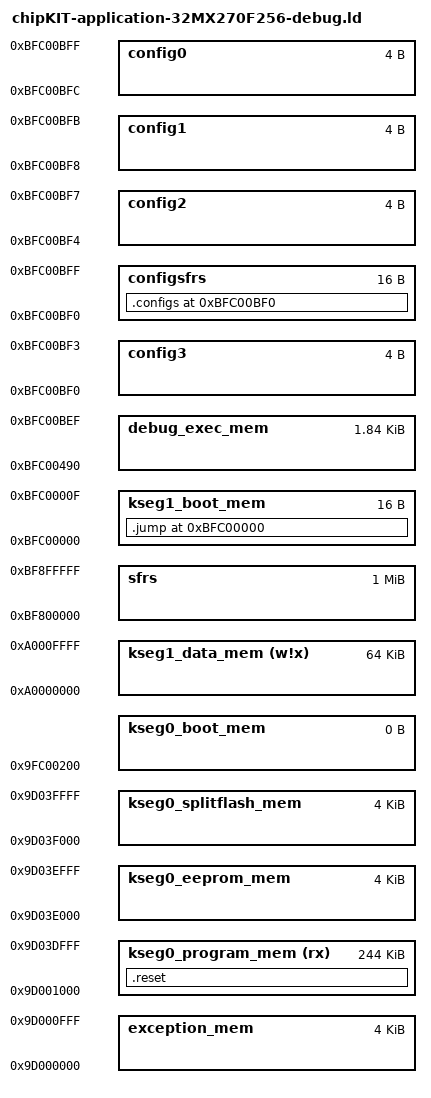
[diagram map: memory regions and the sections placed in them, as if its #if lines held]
/* Default linker script, for normal executables */
OUTPUT_FORMAT("elf32-tradlittlemips")
OUTPUT_ARCH(pic32mx)
ENTRY(_reset)
/*
 * Provide for a minimum stack and heap size
 * - _min_stack_size - represents the minimum space that must be made
 *                     available for the stack.  Can be overridden from
 *                     the command line using the linker's --defsym option.
 * - _min_heap_size  - represents the minimum space that must be made
 *                     available for the heap.  Can be overridden from
 *                     the command line using the linker's --defsym option.
 */
EXTERN (_min_stack_size _min_heap_size)
PROVIDE(_min_stack_size = 0x800) ;
PROVIDE(_min_heap_size = 0x800) ;

/*************************************************************************
 * Processor-specific object file.  Contains SFR definitions.
 *************************************************************************/
INPUT("processor.o")
OPTIONAL("libmchp_peripheral_32MX250F128D.a") 

/*************************************************************************
 * Memory Regions
 *
 * Memory regions without attributes cannot be used for orphaned sections.
 * Only sections specifically assigned to these regions can be allocated
 * into these regions.
 *************************************************************************/
MEMORY
{
  exception_mem              : ORIGIN = 0x9D000000, LENGTH = 0x1000
  kseg0_program_mem    (rx)  : ORIGIN = 0x9D001000, LENGTH = 0x3D000
  kseg0_eeprom_mem           : ORIGIN = 0x9D03E000, LENGTH = 0x1000
  kseg0_splitflash_mem       : ORIGIN = 0x9D03F000, LENGTH = 0x1000
  kseg0_boot_mem             : ORIGIN = 0x9FC00200, LENGTH = 0
#if defined(__DEBUG_D)
  kseg1_boot_mem             : ORIGIN = 0xBFC00000, LENGTH = 0x10 
  debug_exec_mem             : ORIGIN = 0xBFC00490, LENGTH = 0x760
#else
  kseg1_boot_mem             : ORIGIN = 0xBFC00000, LENGTH = 0xBF0 
  debug_exec_mem             : ORIGIN = 0xBFC00490, LENGTH = 0
#endif
  config3                    : ORIGIN = 0xBFC00BF0, LENGTH = 0x4
  config2                    : ORIGIN = 0xBFC00BF4, LENGTH = 0x4
  config1                    : ORIGIN = 0xBFC00BF8, LENGTH = 0x4
  config0                    : ORIGIN = 0xBFC00BFC, LENGTH = 0x4
  kseg1_data_mem       (w!x) : ORIGIN = 0xA0000000, LENGTH = 0x10000
  sfrs                       : ORIGIN = 0xBF800000, LENGTH = 0x100000
  configsfrs                 : ORIGIN = 0xBFC00BF0, LENGTH = 0x10
}

/*************************************************************************
 * Memory Address Equates
 *************************************************************************/
_ebase_address  	    = ORIGIN(exception_mem);
_IMAGE_PTR_TABLE       	= _ebase_address + 0x0F8;
_IMAGE_HEADER_ADDR      = _ebase_address + 0x0FC;
_GEN_EXCPT_ADDR         = _ebase_address + 0x180;
_RESET_ADDR             = ORIGIN(kseg0_program_mem);
_EEPROM_ADDR            = ORIGIN(kseg0_eeprom_mem);
_BEV_EXCPT_ADDR         = 0xBFC00380;
_DBG_EXCPT_ADDR         = 0xBFC00480;
_DBG_CODE_ADDR          = ORIGIN(debug_exec_mem);

/*************************************************************************
 *  Bootloader program directives.
 *  
 * _IMAGE_TYPE
 *
 *  image type:
 */
     
_imageReserved                      = 0x00000000 ;
_imageMPIDE                         = 0x00000001 ;  /* This is a normal MPIDE sketch                                                                                                    */
_imageBootFlashBootloader           = 0x00000002 ;  /* This is a boot flash bootloader                                                                                                  */
_imageProgramFlashBootloader        = 0x00000004 ;  /* This is a program flash bootloader                                                                                               */
_imageSplitFlashBootloader          = 0x00000008 ;  /* This has bootloader code in both boot and program flash                                                                          */

 /*
 *  Instructions for the bootloader
 */
                                                                       
_imageFullFlashEraseLess4KEEProm    = 0x00010000 ;  /* The original bootloader method of erasing all of program flash except the last 4K reserved for eeprom                            */
_imageJustInTimeFlashErase          = 0x00020000 ;  /* Only flash pages written too needed by the sketch is erased                                                                      */
_imageLinkerSpecifiedFlashErase     = 0x00040000 ;  /* The linker defines the flash range to erase                                                                                      */
_imageFullFlashErase                = 0x00080000 ;  /* All of flash is erased                                                                                                           */
_imageExecutionJumpAddress          = 0x01000000 ;  /* the bootloader will jump to the execution jump address immediately after programming                                             */
_imageExecutionJumpToFirstInFlash   = 0x02000000 ;  /* the bootloader will jump to the first sketch loaded in flash ignoring the execution jump address immediately after programming   */
 
/*  
 * _IMAGE_FLASH_SIZE 
 *
 *      Typically _imageJustInTimeFlashErase is selected to just erase the pages
 *      of flash that code is written too; thus leaving all other flash pages untouched.
 *  
 *      If _imageLinkerSpecifiedFlashErase set, then the range
 *      starting from _ebase_address for _IMAGE_FLASH_SIZE bytes are erased.
 *
 *      If _imageFullFlashErase is specified, than the whole flash
 *      as known by the bootloader will be erased. This will erase eeprom as well
 *
 *      if _imageFullFlashEraseLess4KEEProm is set, all of flash less the last 4K is
 *      erased, this is the old default. This bit could be set to make a program flash bootloader
 *      erasing everything but the old flash. If NOTHING is set, this will be the default as this is the old behavior.
 *  
 *  _JUMP_ADDR
 *  
 *      This is the address that the bootloader will jump to start execution
 *      of the sketch. This is almost always _RESET_ADDR.
 *
 *      However, you can specify an alternate entry execution point for example
 *      if you have alternate starup code that, say, shared
 *      the runtime with other sketches or needed some kind of specific handling
 *
 *      Immediately after programming (avrdude upload) the bootloader will typically
 *      jump to the just loaded sketch, no matter where it was loaded in flash.
 *      _imageExecutionJumpToFirstInFlash will tell the bootloader to jump to the first
 *      sketch in flash even if the just loaded one is not at the beginning of flash.
 *      This is useful when programming sketches in slots of flash and then always
 *      jumping to the program-flash loader (vector sketch) as if the board was just reset.
 *      This bit does not effect jumping to a sketch already in flash after reset.
 *      As of today, after reset, the first program in flash will always be jumped to.
 *
 *************************************************************************/
 _IMAGE_TYPE            = _imageMPIDE | _imageJustInTimeFlashErase | _imageExecutionJumpAddress;
 _IMAGE_FLASH_SIZE      = LENGTH(exception_mem) + LENGTH(kseg0_program_mem);
_JUMP_ADDR              = _RESET_ADDR;

SECTIONS
{
#if defined(__DEBUG_D)
  /* Jump from reset vector */
  .jump ORIGIN(kseg1_boot_mem): {
    LONG(0x3C1F9D00)  /* lui ra 0x9d00 */
	LONG(0x37FF1000)  /* ori ra 0x1000 */
	LONG(0x03E00008)  /* jr ra */
	LONG(0x00000000)  /* nop */
  } > kseg1_boot_mem
#else
  /* Insert bootloader */
  .jump ORIGIN(kseg1_boot_mem): {
	LONG(0x401A6000)	/* 0x1FC0_0000 */
	LONG(0x7F5A04C0)	/* 0x1FC0_0004 */
	LONG(0x13400006)	/* 0x1FC0_0008 */
	LONG(0x401A6000)	/* 0x1FC0_000C */
	LONG(0x3C1BFFBF)	/* 0x1FC0_0010 */
	LONG(0x377BFFFF)	/* 0x1FC0_0014 */
	LONG(0x35BD024)		/* 0x1FC0_0018 */
	LONG(0x409A6000)	/* 0x1FC0_001C */
	LONG(0x42000018)	/* 0x1FC0_0020 */
	LONG(0x3C1DA000)	/* 0x1FC0_0024 */
	LONG(0x27BD3FF8)	/* 0x1FC0_0028 */
	LONG(0x3C1CA001)	/* 0x1FC0_002C */
	LONG(0x279C85F0)	/* 0x1FC0_0030 */
	LONG(0x40096002)	/* 0x1FC0_0034 */
	LONG(0x1205820)		/* 0x1FC0_0038 */
	LONG(0x7D2A1E80)	/* 0x1FC0_003C */
	LONG(0x7D494984)	/* 0x1FC0_0040 */
	LONG(0x40896002)	/* 0x1FC0_0044 */
	LONG(0xC0)			/* 0x1FC0_0048 */
	LONG(0x41DCE000)	/* 0x1FC0_004C */
	LONG(0x408B6002)	/* 0x1FC0_0050 */
	LONG(0x3C08A000)	/* 0x1FC0_0054 */
	LONG(0x25080628)	/* 0x1FC0_0058 */
	LONG(0x3C09A000)	/* 0x1FC0_005C */
	LONG(0x25290840)	/* 0x1FC0_0060 */
	LONG(0x10000006)	/* 0x1FC0_0064 */
	LONG(0x0)			/* 0x1FC0_0068 */
	LONG(0xAD000000)	/* 0x1FC0_006C */
	LONG(0xAD000004)	/* 0x1FC0_0070 */
	LONG(0xAD000008)	/* 0x1FC0_0074 */
	LONG(0xAD00000C)	/* 0x1FC0_0078 */
	LONG(0x25080010)	/* 0x1FC0_007C */
	LONG(0x109082B)		/* 0x1FC0_0080 */
	LONG(0x1420FFF9)	/* 0x1FC0_0084 */
	LONG(0x0)			/* 0x1FC0_0088 */
	LONG(0x3C089FC0)	/* 0x1FC0_008C */
	LONG(0x25080A94)	/* 0x1FC0_0090 */
	LONG(0x8D090000)	/* 0x1FC0_0094 */
	LONG(0x11200018)	/* 0x1FC0_0098 */
	LONG(0x25080004)	/* 0x1FC0_009C */
	LONG(0x8D0A0000)	/* 0x1FC0_00A0 */
	LONG(0x25080004)	/* 0x1FC0_00A4 */
	LONG(0x8D0B0000)	/* 0x1FC0_00A8 */
	LONG(0x11600009)	/* 0x1FC0_00AC */
	LONG(0x25080004)	/* 0x1FC0_00B0 */
	LONG(0x910C0000)	/* 0x1FC0_00B4 */
	LONG(0x254AFFFF)	/* 0x1FC0_00B8 */
	LONG(0x25080001)	/* 0x1FC0_00BC */
	LONG(0xA12C0000)	/* 0x1FC0_00C0 */
	LONG(0x1540FFFB)	/* 0x1FC0_00C4 */
	LONG(0x25290001)	/* 0x1FC0_00C8 */
	LONG(0x10000005)	/* 0x1FC0_00CC */
	LONG(0x0)			/* 0x1FC0_00D0 */
	LONG(0xA1200000)	/* 0x1FC0_00D4 */
	LONG(0x254AFFFF)	/* 0x1FC0_00D8 */
	LONG(0x1540FFFD)	/* 0x1FC0_00DC */
	LONG(0x25290001)	/* 0x1FC0_00E0 */
	LONG(0x25080003)	/* 0x1FC0_00E4 */
	LONG(0x240AFFFC)	/* 0x1FC0_00E8 */
	LONG(0x1484024)		/* 0x1FC0_00EC */
	LONG(0x8D090000)	/* 0x1FC0_00F0 */
	LONG(0x1520FFE7)	/* 0x1FC0_00F4 */
	LONG(0x0)			/* 0x1FC0_00F8 */
	LONG(0x3C09BFC0)	/* 0x1FC0_00FC */
	LONG(0x25290000)	/* 0x1FC0_0100 */
	LONG(0x40897801)	/* 0x1FC0_0104 */
	LONG(0x30840000)	/* 0x1FC0_0108 */
	LONG(0x30A50000)	/* 0x1FC0_010C */
	LONG(0x3C089FC0)	/* 0x1FC0_0110 */
	LONG(0x25080BA4)	/* 0x1FC0_0114 */
	LONG(0x1000008)		/* 0x1FC0_0118 */
	LONG(0x0)			/* 0x1FC0_011C */
	LONG(0xFFFFFFFF)	/* 0x1FC0_0120 */
	LONG(0xFFFFFFFF)	/* 0x1FC0_0124 */
	LONG(0xFFFFFFFF)	/* 0x1FC0_0128 */
	LONG(0xFFFFFFFF)	/* 0x1FC0_012C */
	LONG(0xFFFFFFFF)	/* 0x1FC0_0130 */
	LONG(0xFFFFFFFF)	/* 0x1FC0_0134 */
	LONG(0xFFFFFFFF)	/* 0x1FC0_0138 */
	LONG(0xFFFFFFFF)	/* 0x1FC0_013C */
	LONG(0xFFFFFFFF)	/* 0x1FC0_0140 */
	LONG(0xFFFFFFFF)	/* 0x1FC0_0144 */
	LONG(0xFFFFFFFF)	/* 0x1FC0_0148 */
	LONG(0xFFFFFFFF)	/* 0x1FC0_014C */
	LONG(0xFFFFFFFF)	/* 0x1FC0_0150 */
	LONG(0xFFFFFFFF)	/* 0x1FC0_0154 */
	LONG(0xFFFFFFFF)	/* 0x1FC0_0158 */
	LONG(0xFFFFFFFF)	/* 0x1FC0_015C */
	LONG(0xFFFFFFFF)	/* 0x1FC0_0160 */
	LONG(0xFFFFFFFF)	/* 0x1FC0_0164 */
	LONG(0xFFFFFFFF)	/* 0x1FC0_0168 */
	LONG(0xFFFFFFFF)	/* 0x1FC0_016C */
	LONG(0xFFFFFFFF)	/* 0x1FC0_0170 */
	LONG(0xFFFFFFFF)	/* 0x1FC0_0174 */
	LONG(0xFFFFFFFF)	/* 0x1FC0_0178 */
	LONG(0xFFFFFFFF)	/* 0x1FC0_017C */
	LONG(0xFFFFFFFF)	/* 0x1FC0_0180 */
	LONG(0xFFFFFFFF)	/* 0x1FC0_0184 */
	LONG(0xFFFFFFFF)	/* 0x1FC0_0188 */
	LONG(0xFFFFFFFF)	/* 0x1FC0_018C */
	LONG(0xFFFFFFFF)	/* 0x1FC0_0190 */
	LONG(0xFFFFFFFF)	/* 0x1FC0_0194 */
	LONG(0xFFFFFFFF)	/* 0x1FC0_0198 */
	LONG(0xFFFFFFFF)	/* 0x1FC0_019C */
	LONG(0xFFFFFFFF)	/* 0x1FC0_01A0 */
	LONG(0xFFFFFFFF)	/* 0x1FC0_01A4 */
	LONG(0xFFFFFFFF)	/* 0x1FC0_01A8 */
	LONG(0xFFFFFFFF)	/* 0x1FC0_01AC */
	LONG(0xFFFFFFFF)	/* 0x1FC0_01B0 */
	LONG(0xFFFFFFFF)	/* 0x1FC0_01B4 */
	LONG(0xFFFFFFFF)	/* 0x1FC0_01B8 */
	LONG(0xFFFFFFFF)	/* 0x1FC0_01BC */
	LONG(0xFFFFFFFF)	/* 0x1FC0_01C0 */
	LONG(0xFFFFFFFF)	/* 0x1FC0_01C4 */
	LONG(0xFFFFFFFF)	/* 0x1FC0_01C8 */
	LONG(0xFFFFFFFF)	/* 0x1FC0_01CC */
	LONG(0xFFFFFFFF)	/* 0x1FC0_01D0 */
	LONG(0xFFFFFFFF)	/* 0x1FC0_01D4 */
	LONG(0xFFFFFFFF)	/* 0x1FC0_01D8 */
	LONG(0xFFFFFFFF)	/* 0x1FC0_01DC */
	LONG(0xFFFFFFFF)	/* 0x1FC0_01E0 */
	LONG(0xFFFFFFFF)	/* 0x1FC0_01E4 */
	LONG(0xFFFFFFFF)	/* 0x1FC0_01E8 */
	LONG(0xFFFFFFFF)	/* 0x1FC0_01EC */
	LONG(0xFFFFFFFF)	/* 0x1FC0_01F0 */
	LONG(0xFFFFFFFF)	/* 0x1FC0_01F4 */
	LONG(0xFFFFFFFF)	/* 0x1FC0_01F8 */
	LONG(0xFFFFFFFF)	/* 0x1FC0_01FC */
	LONG(0x446CF0F0)	/* 0x1FC0_0200 */
	LONG(0x4344B50D)	/* 0x1FC0_0204 */
	LONG(0x6A00ED43)	/* 0x1FC0_0208 */
	LONG(0x9B606114)	/* 0x1FC0_020C */
	LONG(0x261143C1)	/* 0x1FC0_0210 */
	LONG(0xEE6C6E03)	/* 0x1FC0_0214 */
	LONG(0x43C72E0E)	/* 0x1FC0_0218 */
	LONG(0xEDC34E39)	/* 0x1FC0_021C */
	LONG(0xAB4F610A)	/* 0x1FC0_0220 */
	LONG(0x3240ABAE)	/* 0x1FC0_0224 */
	LONG(0xEAAD3240)	/* 0x1FC0_0228 */
	LONG(0x5A01EA8E)	/* 0x1FC0_022C */
	LONG(0xEA4B6758)	/* 0x1FC0_0230 */
	LONG(0xE8A0EA6C)	/* 0x1FC0_0234 */
	LONG(0x9D03F000)	/* 0x1FC0_0238 */
	LONG(0x7CA5E000)	/* 0x1FC0_023C */
	LONG(0x3C02BF81)	/* 0x1FC0_0240 */
	LONG(0xAC45F420)	/* 0x1FC0_0244 */
	LONG(0x3C02BF81)	/* 0x1FC0_0248 */
	LONG(0xAC46F430)	/* 0x1FC0_024C */
	LONG(0x7CC6E000)	/* 0x1FC0_0250 */
	LONG(0x3C02BF81)	/* 0x1FC0_0254 */
	LONG(0xAC46F440)	/* 0x1FC0_0258 */
	LONG(0x34844000)	/* 0x1FC0_025C */
	LONG(0x3C02BF81)	/* 0x1FC0_0260 */
	LONG(0xAC44F400)	/* 0x1FC0_0264 */
	LONG(0x40034800)	/* 0x1FC0_0268 */
	LONG(0x402821)		/* 0x1FC0_026C */
	LONG(0x40024800)	/* 0x1FC0_0270 */
	LONG(0x431023)		/* 0x1FC0_0274 */
	LONG(0x2C420078)	/* 0x1FC0_0278 */
	LONG(0x1440FFFC)	/* 0x1FC0_027C */
	LONG(0x3C02BF81)	/* 0x1FC0_0280 */
	LONG(0x3C03AA99)	/* 0x1FC0_0284 */
	LONG(0x24636655)	/* 0x1FC0_0288 */
	LONG(0xAC43F410)	/* 0x1FC0_028C */
	LONG(0x3C035566)	/* 0x1FC0_0290 */
	LONG(0x346399AA)	/* 0x1FC0_0294 */
	LONG(0xAC43F410)	/* 0x1FC0_0298 */
	LONG(0x34048000)	/* 0x1FC0_029C */
	LONG(0x3C03BF81)	/* 0x1FC0_02A0 */
	LONG(0xAC64F408)	/* 0x1FC0_02A4 */
	LONG(0x8CA2F400)	/* 0x1FC0_02A8 */
	LONG(0x30428000)	/* 0x1FC0_02AC */
	LONG(0x1440FFFD)	/* 0x1FC0_02B0 */
	LONG(0x0)			/* 0x1FC0_02B4 */
	LONG(0x40024800)	/* 0x1FC0_02B8 */
	LONG(0x40034800)	/* 0x1FC0_02BC */
	LONG(0x621823)		/* 0x1FC0_02C0 */
	LONG(0x2C63000A)	/* 0x1FC0_02C4 */
	LONG(0x1460FFFC)	/* 0x1FC0_02C8 */
	LONG(0x24034000)	/* 0x1FC0_02CC */
	LONG(0x3C02BF81)	/* 0x1FC0_02D0 */
	LONG(0xAC43F404)	/* 0x1FC0_02D4 */
	LONG(0x3E00008)		/* 0x1FC0_02D8 */
	LONG(0x0)			/* 0x1FC0_02DC */
	LONG(0x6A00F400)	/* 0x1FC0_02E0 */
	LONG(0x64F6EA4B)	/* 0x1FC0_02E4 */
	LONG(0x67044DFF)	/* 0x1FC0_02E8 */
	LONG(0xE84CB31C)	/* 0x1FC0_02EC */
	LONG(0xB21CED4C)	/* 0x1FC0_02F0 */
	LONG(0xE34DEB0C)	/* 0x1FC0_02F4 */
	LONG(0x4D00F400)	/* 0x1FC0_02F8 */
	LONG(0xD5043362)	/* 0x1FC0_02FC */
	LONG(0x1027336A)
	LONG(0xE3FDB718)
	LONG(0x2217A740)
	LONG(0x9CC0101F)
	LONG(0xEACC4C04)
	LONG(0x61FBECAA)
	LONG(0x24164281)
	LONG(0x6C04F008)
	LONG(0x6E0067B0)
	LONG(0xD20649FF)
	LONG(0x1E1FD305)
	LONG(0xD707008F)
	LONG(0x93059206)
	LONG(0x29049707)
	LONG(0x6A011007)
	LONG(0xEA4B6905)
	LONG(0x40A0F400)
	LONG(0x17E66790)
	LONG(0xC7406A01)
	LONG(0xF4004B01)
	LONG(0x92044800)
	LONG(0x61D6E843)
	LONG(0xE8A06476)
	LONG(0x1FFFFC00)
	LONG(0xE3000000)
	LONG(0xA0001040)
	LONG(0x676664F5)
	LONG(0x67256704)
	LONG(0x100F6A00)
	LONG(0x468199C0)
	LONG(0xF0082409)
	LONG(0x67B06C01)
	LONG(0x1E1FD204)
	LONG(0xD305008F)
	LONG(0x92049305)
	LONG(0x4A014804)
	LONG(0xEA6A4904)
	LONG(0x647561EF)
	LONG(0x6500E8A0)
	LONG(0x181A64E3)
	LONG(0x6500FE88)
	LONG(0xB22B6BFF)
	LONG(0x6C00F400)
	LONG(0xDA804B01)
	LONG(0xDA60671C)
	LONG(0xDA80B228)
	LONG(0x9890F010)
	LONG(0x801A1F)
	LONG(0x2243DA60)
	LONG(0xA069F070)
	LONG(0x230DEB11)
	LONG(0xAA8AAA6B)
	LONG(0x33603360)
	LONG(0xB421EB8D)
	LONG(0x2305EB8C)
	LONG(0x1A1FB420)
	LONG(0x65000080)
	LONG(0xAA6D2207)
	LONG(0x3360AA8C)
	LONG(0xEB8D3360)
	LONG(0xD874F010)
	LONG(0xAA80AA61)
	LONG(0x33603360)
	LONG(0x5B3CEB8D)
	LONG(0xAA7B6124)
	LONG(0x3360AA9A)
	LONG(0xEB8D3360)
	LONG(0xF0106790)
	LONG(0x44AC4C10)
	LONG(0x6119ED63)
	LONG(0xAA5DAABC)
	LONG(0x32403240)
	LONG(0x5A09EAAD)
	LONG(0x6A086101)
	LONG(0xEC43E473)
	LONG(0x67446001)
	LONG(0xF0506790)
	LONG(0xF050D850)
	LONG(0x10044C10)
	LONG(0x4C01A4A0)
	LONG(0x4B01C3A0)
	LONG(0x42A14AFF)
	LONG(0xF0102DF9)
	LONG(0xEAC09854)
	LONG(0xBF886034)
	LONG(0xBF886018)
	LONG(0x2000000)
	LONG(0x9D000000)
	LONG(0xF0D0675C)
	LONG(0x64C3A266)
	LONG(0xF0D02306)
	LONG(0x2203A24E)
	LONG(0xFCD9181A)
	LONG(0x64436500)
	LONG(0x6500E8A0)
	LONG(0xF4C064FD)
	LONG(0x671CB210)
	LONG(0x67509A60)
	LONG(0x4A10F050)
	LONG(0xFC4F181A)
	LONG(0xF4C0DA61)
	LONG(0xF4C0B400)
	LONG(0x6A00B300)
	LONG(0xDB80DB40)
	LONG(0xB418F4A0)
	LONG(0x6D01F004)
	LONG(0xF4A0DB80)
	LONG(0x9C60B414)
	LONG(0xEBACEDAB)
	LONG(0x6B10DC60)
	LONG(0xB408F4A0)
	LONG(0xF4A0DC60)
	LONG(0xDC40B408)
	LONG(0xB404F4A0)
	LONG(0xF4A0DC40)
	LONG(0x9C40B404)
	LONG(0x4D18F7E3)
	LONG(0xDC40EAAC)
	LONG(0xB418F480)
	LONG(0x6A00F400)
	LONG(0xF51FDC40)
	LONG(0xDC404A00)
	LONG(0xB40CF480)
	LONG(0xF480DC40)
	LONG(0x9A40B20C)
	LONG(0xEA6C6C01)
	LONG(0x67585A01)
	LONG(0xF480EA8E)
	LONG(0xF002B400)
	LONG(0xEDAF9CA0)
	LONG(0x67B85D01)
	LONG(0xF4607501)
	LONG(0x9DA0B514)
	LONG(0xED6C67D8)
	LONG(0x6B01EACC)
	LONG(0xF460250E)
	LONG(0x9CA0B408)
	LONG(0x2D09ED6C)
	LONG(0x6E809CA0)
	LONG(0x2D05EDCC)
	LONG(0x6C409C60)
	LONG(0x5B01EB8C)
	LONG(0xEA6C6778)
	LONG(0xF4406C10)
	LONG(0xDB80B30C)
	LONG(0xF4006C00)
	LONG(0xF050B308)
	LONG(0xDB80C058)
	LONG(0x1A1F2203)
	LONG(0x650000E7)
	LONG(0x1581E1F)
	LONG(0x65006500)
	LONG(0x40024800)
	LONG(0x77F0015B)
	LONG(0x0)
	LONG(0xF0506500)
	LONG(0xF070D85C)
	LONG(0x181AD840)
	LONG(0x6500FEBF)
	LONG(0xB410F400)
	LONG(0xFD21181A)
	LONG(0x1E1F6500)
	LONG(0x65000163)
	LONG(0x40024800)
	LONG(0x77F00166)
	LONG(0x0)
	LONG(0xB3FE6500)
	LONG(0xA0A8F070)
	LONG(0x9880F070)
	LONG(0xE293ED66)
	LONG(0xF070EC63)
	LONG(0x6106D844)
	LONG(0x6C00F400)
	LONG(0xDB80B3F8)
	LONG(0xD840F070)
	LONG(0xA049F070)
	LONG(0x2A03EA11)
	LONG(0xA058F050)
	LONG(0x1A1F2203)
	LONG(0x650000E7)
	LONG(0xFD63181A)
	LONG(0xF0506500)
	LONG(0x22D5A04C)
	LONG(0x984CF070)
	LONG(0xA3A2B3EE)
	LONG(0xE459B4EE)
	LONG(0x42C1C6A0)
	LONG(0x6F00E4D9)
	LONG(0x7511C6E0)
	LONG(0xF07042C2)
	LONG(0xF120D8CC)
	LONG(0x5D126001)
	LONG(0x7502600E)
	LONG(0x5D036052)
	LONG(0x6B016004)
	LONG(0x2516ED6E)
	LONG(0x75031165)
	LONG(0x75066050)
	LONG(0x6009F080)
	LONG(0x7514115F)
	LONG(0x601AF0C0)
	LONG(0x60045D15)
	LONG(0xF0807513)
	LONG(0x11566010)
	LONG(0xEFAE6F1D)
	LONG(0x7548274A)
	LONG(0x1150601C)
	LONG(0xE4D96B01)
	LONG(0xF0704A03)
	LONG(0x6B08C068)
	LONG(0xF050C660)
	LONG(0xF070C0B8)
	LONG(0xF070C0B0)
	LONG(0xE291D84C)
	LONG(0x83A0B3D2)
	LONG(0xC4A04B01)
	LONG(0x2DFB4C01)
	LONG(0x6BFF4A08)
	LONG(0xD84CF070)
	LONG(0xB2CE4B01)
	LONG(0xA3A31134)
	LONG(0xA324A3E5)
	LONG(0x650DA366)
	LONG(0x654B35E0)
	LONG(0x332035A0)
	LONG(0x67A8EBAD)
	LONG(0x67AAEBAD)
	LONG(0x35A0F600)
	LONG(0xF070EBAD)
	LONG(0xE4D9D874)
	LONG(0xC6606768)
	LONG(0xE44D67AA)
	LONG(0xC3E4C323)
	LONG(0x4A06C3A5)
	LONG(0xA343100D)
	LONG(0xA364B4BF)
	LONG(0xC260E449)
	LONG(0xA3631113)
	LONG(0xE56DB5BC)
	LONG(0xE4D1A360)
	LONG(0x4A03C460)
	LONG(0xD84CF070)
	LONG(0xE4D91109)
	LONG(0xA3C6C6E0)
	LONG(0xC5C3E455)
	LONG(0x7630C5E4)
	LONG(0xF07042A5)
	LONG(0x610DD8AC)
	LONG(0xE4B1A368)
	LONG(0x6B502B03)
	LONG(0x1016C460)
	LONG(0x4A067301)
	LONG(0x60016B49)
	LONG(0xC4606B43)
	LONG(0x76201010)
	LONG(0x76286002)
	LONG(0xB2A76109)
	LONG(0xE2A96B01)
	LONG(0x4D01EB6B)
	LONG(0xF070C260)
	LONG(0x1005D8AC)
	LONG(0xC4E0E4B1)
	LONG(0xF0704A06)
	LONG(0xF070D84C)
	LONG(0xB39F984C)
	LONG(0x6C00E34D)
	LONG(0x4A01C380)
	LONG(0xA38417CB)
	LONG(0x3480A343)
	LONG(0xF6003480)
	LONG(0xEA8D3240)
	LONG(0xA365A386)
	LONG(0x3360EA8D)
	LONG(0x3244EA6D)
	LONG(0x9878F010)
	LONG(0xA3431041)
	LONG(0x3240A364)
	LONG(0x6B04EA6D)
	LONG(0x4223EB6B)
	LONG(0x6762E96C)
	LONG(0xB4931006)
	LONG(0xE3916D01)
	LONG(0xC4A0EDAB)
	LONG(0xEB234B01)
	LONG(0xF01061F8)
	LONG(0x231CA07C)
	LONG(0x5900F100)
	LONG(0xF0706116)
	LONG(0xF1E09898)
	LONG(0xEB8C6B1F)
	LONG(0xB38A2B10)
	LONG(0x43A19B60)
	LONG(0xF010250C)
	LONG(0xF01098B8)
	LONG(0xE4B7D870)
	LONG(0xEC6CB486)
	LONG(0xD898F010)
	LONG(0xF070E591)
	LONG(0x6B00D898)
	LONG(0xC07CF010)
	LONG(0x98B8F070)
	LONG(0x6785D214)
	LONG(0xB81A1F)
	LONG(0xF070E1B5)
	LONG(0xB57B9898)
	LONG(0xDA1A1F)
	LONG(0xF070362A)
	LONG(0x92149878)
	LONG(0xF070E349)
	LONG(0x1082D858)
	LONG(0xA364A383)
	LONG(0x9858F070)
	LONG(0xEC6D3480)
	LONG(0x1020E44D)
	LONG(0xB775B574)
	LONG(0xE5F5ED4C)
	LONG(0x35AA35A2)
	LONG(0xE7B5B773)
	LONG(0xF400A5A0)
	LONG(0xEC8B6C00)
	LONG(0x7501EC4C)
	LONG(0x4C00F400)
	LONG(0x61016DFF)
	LONG(0xEB836D00)
	LONG(0x67836009)
	LONG(0xA2E01007)
	LONG(0xE625B161)
	LONG(0xC1E0EFAD)
	LONG(0x4A014E01)
	LONG(0x61F7EA83)
	LONG(0x61DEEA63)
	LONG(0xD858F070)
	LONG(0xE2C9B25B)
	LONG(0x4E016B00)
	LONG(0xF070C260)
	LONG(0x104ED8CC)
	LONG(0x9890F010)
	LONG(0x801A1F)
	LONG(0x67226500)
	LONG(0x67B0223B)
	LONG(0xF0304284)
	LONG(0x1A1F4D00)
	LONG(0x6E0100DA)
	LONG(0x67B04187)
	LONG(0xF0304C09)
	LONG(0x1A1F4D04)
	LONG(0x6E0100DA)
	LONG(0x67B04187)
	LONG(0xF0304C05)
	LONG(0x1A1F4D08)
	LONG(0x6E0100DA)
	LONG(0x67B04187)
	LONG(0xF0304C35)
	LONG(0x1A1F4D0C)
	LONG(0x6E0100DA)
	LONG(0xA96AA94B)
	LONG(0x32403240)
	LONG(0xB34CEA6D)
	LONG(0x2B19EB4C)
	LONG(0xEB4CB34B)
	LONG(0xA98F230C)
	LONG(0x3480A94E)
	LONG(0x3480A9B1)
	LONG(0x35A0EC4D)
	LONG(0x35A0A950)
	LONG(0xE595ED4D)
	LONG(0xB3451007)
	LONG(0x2202EA6C)
	LONG(0x1001B544)
	LONG(0xB42EB544)
	LONG(0xB81A1F)
	LONG(0x6A016500)
	LONG(0xF0706BFF)
	LONG(0x4B01C049)
	LONG(0xDA60B227)
	LONG(0x6A1B67DD)
	LONG(0xF050C650)
	LONG(0xF070A080)
	LONG(0x6D0E984C)
	LONG(0x6D1BC6B4)
	LONG(0x3343C691)
	LONG(0xC672ECAE)
	LONG(0xC653EB8E)
	LONG(0x6E0EEA6E)
	LONG(0x6D05EACE)
	LONG(0xC058F030)
	LONG(0x1181A1F)
	LONG(0xF0700404)
	LONG(0xF03098AC)
	LONG(0x6A00A078)
	LONG(0xB4211005)
	LONG(0xA480E291)
	LONG(0xEB8E4A01)
	LONG(0xE9AE6722)
	LONG(0xB41D29F8)
	LONG(0xC078F030)
	LONG(0x1181A1F)
	LONG(0x67906500)
	LONG(0x4C18F030)
	LONG(0x1181A1F)
	LONG(0xF0706D01)
	LONG(0xF050D82C)
	LONG(0x161DC02C)
	LONG(0xBF80F600)
	LONG(0xAA996655)
	LONG(0xBF80F230)
	LONG(0x556699AA)
	LONG(0xBF80F200)
	LONG(0xBF886158)
	LONG(0xBF886000)
	LONG(0xBF886100)
	LONG(0xBF80F200)
	LONG(0xBF886014)
	LONG(0xBF886034)
	LONG(0xBF886120)
	LONG(0x9D000000)
	LONG(0xBF886130)
	LONG(0xBF80F600)
	LONG(0xBF886134)
	LONG(0x9D03F4E1)
	LONG(0x2625A0)
	LONG(0xBF88603C)
	LONG(0xA0000840)
	LONG(0xA0000C40)
	LONG(0x9FC00BB4)
	LONG(0xBF886038)
	LONG(0xA000113C)
	LONG(0xA000084C)
	LONG(0xA0000944)
	LONG(0xFFFF0000)
	LONG(0x1FFFFC00)
	LONG(0xE3000000)
	LONG(0xA0001040)
	LONG(0x20000)
	LONG(0x40000)
	LONG(0x80000)
	LONG(0x9D03F000)
	LONG(0x9D03E000)
	LONG(0xF030675C)
	LONG(0xF030A278)
	LONG(0xEC119ABC)
	LONG(0x5D07EB8E)
	LONG(0xC278F030)
	LONG(0xF7D36050)
	LONG(0x36C06E00)
	LONG(0x35A836C0)
	LONG(0x4E04F201)
	LONG(0x9EA0E5D9)
	LONG(0x6500ED80)
	LONG(0x9FC00A21)
	LONG(0x9FC00A31)
	LONG(0x9FC00A39)
	LONG(0x9FC00A43)
	LONG(0x9FC00A51)
	LONG(0x9FC00A61)
	LONG(0x9FC00A81)
	LONG(0x6103741B)
	LONG(0xF0306B01)
	LONG(0xF030DA7C)
	LONG(0xE8A0C298)
	LONG(0xC280F050)
	LONG(0x10216B02)
	LONG(0xF0503480)
	LONG(0x6B03DA84)
	LONG(0xF050101C)
	LONG(0xEB8D9A64)
	LONG(0xDA64F050)
	LONG(0x10156B04)
	LONG(0xEC6E6B0E)
	LONG(0x2C116B00)
	LONG(0xDA88F050)
	LONG(0x100D6B05)
	LONG(0x9A68F050)
	LONG(0xE575B50B)
	LONG(0xF050C582)
	LONG(0x4B019A84)
	LONG(0xDA68F050)
	LONG(0x2B0BEB8E)
	LONG(0xF0306B06)
	LONG(0xE8A0DA7C)
	LONG(0x6B012B03)
	LONG(0xC26CF050)
	LONG(0xF0306B00)
	LONG(0xE8A0DA7C)
	LONG(0xA0000840)
	LONG(0xA0000840)
	LONG(0x9FC)
	LONG(0x0)
	LONG(0xA0000628)
	LONG(0x44)
	LONG(0x0)
	LONG(0xA0000600)
	LONG(0x20)
	LONG(0x1)
	LONG(0x9D000000)
	LONG(0x9D001000)
	LONG(0x9D000000)
	LONG(0x1)
	LONG(0x1000303)
	LONG(0x50009)
	LONG(0x330F1632)
	LONG(0x600)
	LONG(0xA0001800)
	LONG(0x200)
	LONG(0x0)
	LONG(0xA000066C)
	LONG(0x38)
	LONG(0x0)
	LONG(0xA00006C0)
	LONG(0x180)
	LONG(0x0)
	LONG(0xA00016AC)
	LONG(0x68)
	LONG(0x1)
	LONG(0x4090304)
	LONG(0x4D032A)
	LONG(0x6A0061)
	LONG(0x6E0065)
	LONG(0x6F006B)
	LONG(0x540020)
	LONG(0x630065)
	LONG(0x6E0068)
	LONG(0x6C006F)
	LONG(0x67006F)
	LONG(0x650069)
	LONG(0x31C0073)
	LONG(0x680063)
	LONG(0x700069)
	LONG(0x49004B)
	LONG(0x200054)
	LONG(0x65004C)
	LONG(0x6E006E)
	LONG(0x31E0079)
	LONG(0x4B0043)
	LONG(0x300030)
	LONG(0x300030)
	LONG(0x300030)
	LONG(0x300030)
	LONG(0x300030)
	LONG(0x300030)
	LONG(0xA000123C)
	LONG(0x470)
	LONG(0x0)
	LONG(0xA00006A4)
	LONG(0x8)
	LONG(0x0)
	LONG(0xA0000620)
	LONG(0x8)
	LONG(0x1)
	LONG(0x1C200)
	LONG(0x80000)
	LONG(0x0)
	LONG(0x22222222)
	LONG(0x77F0011F)
	LONG(0x0)
	LONG(0x1000FFFF)
	LONG(0x0)
	LONG(0x354B5453)
	LONG(0x325F3030)
	LONG(0x65000000)
	LONG(0xFFFFFFFF)
	LONG(0xFFFFFFFF)
	LONG(0xFFFFFFFF)
	LONG(0xFFFFFFFF)
	LONG(0xFFFFFFFF)
	LONG(0xFFFFFFFF)
	LONG(0xFFFFFFFF)
	LONG(0xFFFFFFFF)
	LONG(0xFFFFFFFF)
	LONG(0xFFFFFFFF)
	LONG(0xFFFFFFFF)
	LONG(0xFFFFFFFF)
  } > kseg1_boot_mem
  
  .btl_pt2 ORIGIN(kseg0_splitflash_mem) : {
	LONG(0x677CA481)
	LONG(0x67467420)
	LONG(0x7421600D)
	LONG(0x74016017)
	LONG(0x60046766)
	LONG(0x6C00101E)
	LONG(0x4D01C580)
	LONG(0x43814BFF)
	LONG(0xE8A02CFA)
	LONG(0xF0304547)
	LONG(0x10044B10)
	LONG(0x4D01A580)
	LONG(0x4B01C380)
	LONG(0x61FAED4A)
	LONG(0x6A00E820)
	LONG(0xF0304587)
	LONG(0x10044B10)
	LONG(0x4B01A3C0)
	LONG(0x4D01C5C0)
	LONG(0x61FAED8A)
	LONG(0xE820E8A0)
	LONG(0x65006A00)
	LONG(0x4267B212)
	LONG(0x4B3964E3)
	LONG(0x6C00671C)
	LONG(0x4A04DA80)
	LONG(0x61FBEA6A)
	LONG(0xA08CF0D0)
	LONG(0x67E66E00)
	LONG(0xFD39181A)
	LONG(0xF0D06DFF)
	LONG(0x6E00A085)
	LONG(0x181A67E6)
	LONG(0x6DFFFD39)
	LONG(0xA09CF0B0)
	LONG(0xB6066D00)
	LONG(0xFD39181A)
	LONG(0xF0B06F40)
	LONG(0xEAC09854)
	LONG(0xE8A06463)
	LONG(0xA000123C)
	LONG(0xA000127C)
	LONG(0x64F5EC11)
	LONG(0x2C18671C)
	LONG(0xF0B06A01)
	LONG(0xF0D0C098)
	LONG(0x6900C04E)
	LONG(0xE5291009)
	LONG(0xD504A280)
	LONG(0x2761A1F)
	LONG(0x9605D605)
	LONG(0x49019504)
	LONG(0x61F5E9C2)
	LONG(0xA09CF0B0)
	LONG(0xB6166D00)
	LONG(0x10216F40)
	LONG(0xA05AF0B0)
	LONG(0x3348B414)
	LONG(0x6D00E46D)
	LONG(0x4A01DBA0)
	LONG(0xEA6C6B0F)
	LONG(0xE4B13548)
	LONG(0xF0B09CE0)
	LONG(0x5701C05A)
	LONG(0xF0B06113)
	LONG(0xEC4AA09B)
	LONG(0x4C016104)
	LONG(0xF0B0EC6C)
	LONG(0x6B3FC09B)
	LONG(0xB609EA78)
	LONG(0xF0D0EA12)
	LONG(0x6D01A08C)
	LONG(0x181AE659)
	LONG(0x6500FD39)
	LONG(0xE8206475)
	LONG(0x65006A00)
	LONG(0xA000127C)
	LONG(0xA000123C)
	LONG(0xA00012BC)
	LONG(0x9A60B287)
	LONG(0x3362F700)
	LONG(0x60055B0A)
	LONG(0xF7009A40)
	LONG(0x4A303242)
	LONG(0x9A401004)
	LONG(0x3242F700)
	LONG(0xB3814A37)
	LONG(0xC350F040)
	LONG(0x9A60B27E)
	LONG(0xF6006C0F)
	LONG(0xEB8C3362)
	LONG(0x60075B0A)
	LONG(0x6B0F9A40)
	LONG(0x3242F600)
	LONG(0x4A30EA6C)
	LONG(0x9A401006)
	LONG(0xF6006B0F)
	LONG(0xEA6C3242)
	LONG(0xB3754A37)
	LONG(0xC352F040)
	LONG(0x9A60B272)
	LONG(0xF5006C0F)
	LONG(0xEB8C3362)
	LONG(0x60075B0A)
	LONG(0x6B0F9A40)
	LONG(0x3242F500)
	LONG(0x4A30EA6C)
	LONG(0x9A401006)
	LONG(0xF5006B0F)
	LONG(0xEA6C3242)
	LONG(0xEA114A37)
	LONG(0xF040B368)
	LONG(0xB266C354)
	LONG(0x6C0F9A60)
	LONG(0x33623362)
	LONG(0x5B0AEB8C)
	LONG(0x9A406007)
	LONG(0x32426B0F)
	LONG(0xEA6C3242)
	LONG(0x10064A30)
	LONG(0x6B0F9A40)
	LONG(0x32423242)
	LONG(0x4A37EA6C)
	LONG(0xB35CEA11)
	LONG(0xC356F040)
	LONG(0x9A60B259)
	LONG(0x33626C0F)
	LONG(0xEB8C3372)
	LONG(0x60075B0A)
	LONG(0x6B0F9A40)
	LONG(0x32523242)
	LONG(0x4A30EA6C)
	LONG(0x9A401006)
	LONG(0x32426B0F)
	LONG(0xEA6C3252)
	LONG(0xEA114A37)
	LONG(0xF040B34F)
	LONG(0xB24DC358)
	LONG(0x6C0F9A60)
	LONG(0xEB8C3362)
	LONG(0x60065B0A)
	LONG(0x6B0F9A40)
	LONG(0xEA6C3242)
	LONG(0x10054A30)
	LONG(0x6B0F9A40)
	LONG(0xEA6C3242)
	LONG(0xEA114A37)
	LONG(0xF040B344)
	LONG(0xB242C35A)
	LONG(0x6C0F9A60)
	LONG(0xEB8C3372)
	LONG(0x60065B0A)
	LONG(0x6B0F9A40)
	LONG(0xEA6C3252)
	LONG(0x10054A30)
	LONG(0x6B0F9A40)
	LONG(0xEA6C3252)
	LONG(0xEA114A37)
	LONG(0xF040B339)
	LONG(0xB237C35C)
	LONG(0x6C0F9A60)
	LONG(0x5B0AEB8C)
	LONG(0x9A406005)
	LONG(0xEA6C6B0F)
	LONG(0x10044A30)
	LONG(0x6B0F9A40)
	LONG(0x4A37EA6C)
	LONG(0xB330EA11)
	LONG(0xC35EF040)
	LONG(0x9A60B22F)
	LONG(0x33626C0F)
	LONG(0xEB8C3372)
	LONG(0x60075B0A)
	LONG(0x6B0F9A40)
	LONG(0x32523242)
	LONG(0x4A30EA6C)
	LONG(0x9A401006)
	LONG(0x32426B0F)
	LONG(0xEA6C3252)
	LONG(0xEA114A37)
	LONG(0xF060B323)
	LONG(0xB223C340)
	LONG(0x6C0F9A60)
	LONG(0xEB8C3362)
	LONG(0x60065B0A)
	LONG(0x6B0F9A40)
	LONG(0xEA6C3242)
	LONG(0x10054A30)
	LONG(0x6B0F9A40)
	LONG(0xEA6C3242)
	LONG(0xEA114A37)
	LONG(0xF060B318)
	LONG(0xB218C342)
	LONG(0x6C0F9A60)
	LONG(0xEB8C3372)
	LONG(0x60065B0A)
	LONG(0x6B0F9A40)
	LONG(0xEA6C3252)
	LONG(0x10054A30)
	LONG(0x6B0F9A40)
	LONG(0xEA6C3252)
	LONG(0xEA114A37)
	LONG(0xF060B30D)
	LONG(0xB20DC344)
	LONG(0x6C0F9A60)
	LONG(0x5B0AEB8C)
	LONG(0x9A406005)
	LONG(0xEA6C6B0F)
	LONG(0x10044A30)
	LONG(0x6B0F9A40)
	LONG(0x4A37EA6C)
	LONG(0xB304EA11)
	LONG(0xC346F060)
	LONG(0x6500E8A0)
	LONG(0xBF80F220)
	LONG(0xA00016AC)
	LONG(0xBFC00BF0)
	LONG(0x673C64F5)
	LONG(0xA146F0D0)
	LONG(0x226F6705)
	LONG(0xA158F0B0)
	LONG(0x45672A6C)
	LONG(0x4B376A3F)
	LONG(0x2A01EB5B)
	LONG(0xEA12E8E5)
	LONG(0xF0B04A01)
	LONG(0x6D10A17A)
	LONG(0x67CC658B)
	LONG(0xA17BF0B0)
	LONG(0xE67B4E10)
	LONG(0x2D01EEBA)
	LONG(0xEE10E8E5)
	LONG(0x67C52E01)
	LONG(0x6007EE42)
	LONG(0x181AD204)
	LONG(0xD405FD63)
	LONG(0x94059204)
	LONG(0xB52817E8)
	LONG(0xE5493268)
	LONG(0x6D3F9A40)
	LONG(0xE8A3E557)
	LONG(0x600165AA)
	LONG(0x6F3F67B0)
	LONG(0x67EDEBF8)
	LONG(0x652CEA12)
	LONG(0xB221E75D)
	LONG(0x654FE75D)
	LONG(0x1009650D)
	LONG(0xA7E067E9)
	LONG(0xC2E0674A)
	LONG(0x4A0167E9)
	LONG(0x654A4F01)
	LONG(0x6748652F)
	LONG(0x650A4AFF)
	LONG(0x2AF24A01)
	LONG(0xB2163768)
	LONG(0x650AE2E9)
	LONG(0xE5E967ED)
	LONG(0x67E87610)
	LONG(0xE0A3DF40)
	LONG(0x200B6001)
	LONG(0x6A0F4B01)
	LONG(0x2805EB4C)
	LONG(0xF0B07610)
	LONG(0x6006C17B)
	LONG(0xE4B11014)
	LONG(0xF0B017C6)
	LONG(0x100FC17B)
	LONG(0x6B3F674C)
	LONG(0x3748EA78)
	LONG(0xEB12B207)
	LONG(0xB607E2E9)
	LONG(0xA18CF0D0)
	LONG(0x6D019AE0)
	LONG(0xFD39181A)
	LONG(0x6475E679)
	LONG(0x6500E8A0)
	LONG(0xA000123C)
	LONG(0xA00012BC)
	LONG(0x671C64E3)
	LONG(0xA059F0B0)
	LONG(0xF0B0220A)
	LONG(0x6D00A09C)
	LONG(0x181AB605)
	LONG(0x6F40FD39)
	LONG(0xF0B06A00)
	LONG(0x6463C059)
	LONG(0x6500E8A0)
	LONG(0xA000127C)
	LONG(0x4267B210)
	LONG(0x4B3964C3)
	LONG(0xDAA06D00)
	LONG(0xEA6A4A04)
	LONG(0x675C61FB)
	LONG(0xDA94F0B0)
	LONG(0xB40CB60B)
	LONG(0x181AB50C)
	LONG(0x6500FE7B)
	LONG(0x181AB40B)
	LONG(0x6D12FE7F)
	LONG(0x181AB40A)
	LONG(0x6D43FE82)
	LONG(0x181AB409)
	LONG(0x6D68FE85)
	LONG(0xE8A06443)
	LONG(0xA000123C)
	LONG(0x9D03F0A9)
	LONG(0x9D03F059)
	LONG(0x9D03F001)
	LONG(0x9D03FB78)
	LONG(0x9D03FB8C)
	LONG(0xA00016AC)
	LONG(0x6500E8A0)
	LONG(0x75FFED11)
	LONG(0x602664A1)
	LONG(0xEC586A60)
	LONG(0xEA12B321)
	LONG(0xA244E349)
	LONG(0x6001EAE2)
	LONG(0x6A6067E2)
	LONG(0x3084EC58)
	LONG(0xE2A9EA12)
	LONG(0xA342E34D)
	LONG(0x35A4E515)
	LONG(0x675CE2B5)
	LONG(0x9A5CF070)
	LONG(0xE2B535AC)
	LONG(0xEE4CB217)
	LONG(0x9D40DDC1)
	LONG(0x6B88A340)
	LONG(0xF360EA6D)
	LONG(0xEF6C4B17)
	LONG(0x37E037E0)
	LONG(0xDD40EAED)
	LONG(0x24016B00)
	LONG(0x6A0D6B10)
	LONG(0xEA6D7401)
	LONG(0x5402600C)
	LONG(0x24066002)
	LONG(0x74021011)
	LONG(0x74036009)
	LONG(0x100C600A)
	LONG(0xB309EA11)
	LONG(0xEA111008)
	LONG(0x1005B308)
	LONG(0xB308EA11)
	LONG(0xEA111002)
	LONG(0xDB40B307)
	LONG(0xE8A06421)
	LONG(0xA00006C0)
	LONG(0x1FFFFFFF)
	LONG(0xBF885300)
	LONG(0xBF885310)
	LONG(0xBF885320)
	LONG(0xBF885330)
	LONG(0x671C64F5)
	LONG(0x98DCF070)
	LONG(0x2613F200)
	LONG(0xB20CF420)
	LONG(0x69089A40)
	LONG(0xF160EA2C)
	LONG(0xF420221E)
	LONG(0x9A40B204)
	LONG(0xE94C6DF0)
	LONG(0xED4C5901)
	LONG(0x67386C60)
	LONG(0x35B36B01)
	LONG(0xED98E96E)
	LONG(0xEB4C6B04)
	LONG(0xEB12650B)
	LONG(0xB204F400)
	LONG(0xE331658C)
	LONG(0xA4E0E291)
	LONG(0xA4E25F01)
	LONG(0x33786778)
	LONG(0xC4605F01)
	LONG(0xC4626778)
	LONG(0xE42534A4)
	LONG(0x5C016788)
	LONG(0x770167F8)
	LONG(0x31246778)
	LONG(0x312CE165)
	LONG(0x99C0E625)
	LONG(0xECCC6C3C)
	LONG(0x740D348B)
	LONG(0x6111F0E0)
	LONG(0xB6F29981)
	LONG(0xECCDB1F2)
	LONG(0x99C06F21)
	LONG(0xEB12EFEB)
	LONG(0xD9C0EEEC)
	LONG(0xE2656F01)
	LONG(0xC1E68CC3)
	LONG(0x656F6778)
	LONG(0xD963A4E0)
	LONG(0x676CD962)
	LONG(0xEF6C654F)
	LONG(0x2F14F0A0)
	LONG(0x8CE1A461)
	LONG(0x650F7306)
	LONG(0x6179652B)
	LONG(0xC1466A09)
	LONG(0x720132E3)
	LONG(0xF0906118)
	LONG(0xEAC29858)
	LONG(0x67C26001)
	LONG(0xED786B60)
	LONG(0xEB12B2DC)
	LONG(0x4B10E271)
	LONG(0xDCC3E34D)
	LONG(0x9854F090)
	LONG(0xA2801004)
	LONG(0xC3804A01)
	LONG(0x4EFF4B01)
	LONG(0x2CF94681)
	LONG(0x7202104E)
	LONG(0xF0906118)
	LONG(0xEAC29850)
	LONG(0x67C26001)
	LONG(0xED786B60)
	LONG(0xEB12B2CF)
	LONG(0x4B10E271)
	LONG(0xDCC3E34D)
	LONG(0x984CF090)
	LONG(0xA2801004)
	LONG(0xC3804A01)
	LONG(0x4EFF4B01)
	LONG(0x2CF94681)
	LONG(0x72031034)
	LONG(0x6767612E)
	LONG(0xF090EB11)
	LONG(0xF09098E8)
	LONG(0x6A009884)
	LONG(0xE4451003)
	LONG(0xE229A120)
	LONG(0x43214BFF)
	LONG(0xE449290E)
	LONG(0xEE62A260)
	LONG(0x67666001)
	LONG(0xED986C60)
	LONG(0xEC12B6BB)
	LONG(0x4C10E69D)
	LONG(0xE4D1DF63)
	LONG(0xEAE2100E)
	LONG(0x6A6061EA)
	LONG(0xB3B6ED58)
	LONG(0xE349EA12)
	LONG(0xDA636B00)
	LONG(0xA2C0100C)
	LONG(0xC4C04A01)
	LONG(0x4BFF4C01)
	LONG(0x2EF943C1)
	LONG(0x6B061004)
	LONG(0x2A01EA6E)
	LONG(0x6A60D943)
	LONG(0xB2ACED58)
	LONG(0x45C7ED12)
	LONG(0xE2B54E09)
	LONG(0xA5E4E659)
	LONG(0xEAE29D43)
	LONG(0x67E26034)
	LONG(0x73011032)
	LONG(0x67AA6110)
	LONG(0xF0807502)
	LONG(0xF0806102)
	LONG(0xAC622F00)
	LONG(0xEB8C6C0F)
	LONG(0xEB98678C)
	LONG(0xE269EB12)
	LONG(0xC2E1C2E0)
	LONG(0x73051076)
	LONG(0x67486104)
	LONG(0xC048F0B0)
	LONG(0x73091070)
	LONG(0xF0D06109)
	LONG(0x678B9848)
	LONG(0xF0D04A01)
	LONG(0xF0D0D848)
	LONG(0x1065C086)
	LONG(0x750867A9)
	LONG(0x6C096162)
	LONG(0xA1E4EB12)
	LONG(0x6C01C186)
	LONG(0xECE24B10)
	LONG(0xC190D983)
	LONG(0x6001E359)
	LONG(0x6C0067E4)
	LONG(0x10576D01)
	LONG(0x35FE67EA)
	LONG(0xEB122511)
	LONG(0xE34D4B10)
	LONG(0x9840F0B0)
	LONG(0xEA4067A3)
	LONG(0x6C09D304)
	LONG(0x9304C186)
	LONG(0x6C00D943)
	LONG(0x67C36D01)
	LONG(0x104367E2)
	LONG(0xEB122608)
	LONG(0x4B106C00)
	LONG(0x67A4D9C3)
	LONG(0xA1E4E279)
	LONG(0x6790103A)
	LONG(0xF0B06D00)
	LONG(0xF0B09840)
	LONG(0x67C54C0C)
	LONG(0xB37C102D)
	LONG(0x36C3EE6C)
	LONG(0x2D4636C3)
	LONG(0xA2669961)
	LONG(0x2B2DEB8E)
	LONG(0x610E7409)
	LONG(0x9AE39A62)
	LONG(0xEBEAE66D)
	LONG(0x6005DA62)
	LONG(0x4E0943C7)
	LONG(0x6D016C00)
	LONG(0x6C00100D)
	LONG(0x101767A4)
	LONG(0x9AE39A62)
	LONG(0xEBEAE66D)
	LONG(0x6007DA62)
	LONG(0x6C0043C7)
	LONG(0x67A44E09)
	LONG(0xE77FE2D9)
	LONG(0x6790100C)
	LONG(0x9840F0B0)
	LONG(0x4C0CF0B0)
	LONG(0x67C3B567)
	LONG(0x6C00EAC0)
	LONG(0x67C46D01)
	LONG(0x181A67E4)
	LONG(0x6500FD39)
	LONG(0xF0B01023)
	LONG(0x2406A088)
	LONG(0x9B40B361)
	LONG(0xC0A8F0B0)
	LONG(0xDB40EA8D)
	LONG(0x6B00B259)
	LONG(0x6C00C260)
	LONG(0x67D06B40)
	LONG(0x67A4C261)
	LONG(0x4E0CF0B0)
	LONG(0x17E76F08)
	LONG(0xA045F0D0)
	LONG(0x250AED4E)
	LONG(0xEC4E6A09)
	LONG(0xB5519961)
	LONG(0xF0B05C01)
	LONG(0x67989844)
	LONG(0xED6DEA40)
	LONG(0xB24A6B08)
	LONG(0xB249DA60)
	LONG(0x6B019A40)
	LONG(0x2278EA6C)
	LONG(0x6B006A00)
	LONG(0xC04EF0D0)
	LONG(0xC046F0D0)
	LONG(0xDA60B24A)
	LONG(0x9A60B246)
	LONG(0xEB8D6C02)
	LONG(0x9A60DA60)
	LONG(0xEB8C4CFB)
	LONG(0xF070DA60)
	LONG(0xF100985C)
	LONG(0x10034260)
	LONG(0xC2806C00)
	LONG(0xEA6A4A01)
	LONG(0xB23B61FB)
	LONG(0x1003B340)
	LONG(0xC2806C00)
	LONG(0xEA6A4A01)
	LONG(0xF09061FB)
	LONG(0xA2679854)
	LONG(0xC264B235)
	LONG(0x986CF090)
	LONG(0x9890F090)
	LONG(0x102E6A00)
	LONG(0xA5C1E355)
	LONG(0x61277605)
	LONG(0x7602A5C3)
	LONG(0xA5C26114)
	LONG(0x270537DE)
	LONG(0xEEEC6F0F)
	LONG(0xC0CCF0D0)
	LONG(0x6F0F1004)
	LONG(0xF0B0EEEC)
	LONG(0x6F60C0DC)
	LONG(0xA5A4EEF8)
	LONG(0xB726EE12)
	LONG(0xC6A4E7D9)
	LONG(0x76031010)
	LONG(0xA5E2610E)
	LONG(0xEEEC6E0F)
	LONG(0xEEF86F60)
	LONG(0xC0C5F0D0)
	LONG(0xA5A4EE12)
	LONG(0xE7D9B71E)
	LONG(0x6D01C6A4)
	LONG(0xE355C6A5)
	LONG(0xE2A9A5A0)
	LONG(0x61D0EA82)
	LONG(0x6AFFB117)
	LONG(0xD940B31F)
	LONG(0x6C189B40)
	LONG(0xDB40EA8D)
	LONG(0x985CF090)
	LONG(0xB214EAC0)
	LONG(0xC2606B00)
	LONG(0x6B406C00)
	LONG(0xC26167D0)
	LONG(0xF0B067A4)
	LONG(0x181A4E0C)
	LONG(0x6F08FD39)
	LONG(0xD9406A01)
	LONG(0x9B40B30A)
	LONG(0xEA8C6C10)
	LONG(0x6A00220C)
	LONG(0xF0D0B510)
	LONG(0xF0D0C04E)
	LONG(0x6E11C046)
	LONG(0xEECB9D40)
	LONG(0xDD40EACC)
	LONG(0x6475DB80)
	LONG(0x6500E8A0)
	LONG(0xBF885200)
	LONG(0xBF885240)
	LONG(0xA00006C0)
	LONG(0xA0000000)
	LONG(0xBF885250)
	LONG(0x3FF0000)
	LONG(0xA00006D0)
	LONG(0xBF885260)
	LONG(0xA0000840)
	LONG(0xBF885210)
	LONG(0xF090675C)
	LONG(0xF0B0DA9C)
	LONG(0xF0B0DAA0)
	LONG(0xE8A0DAC4)
	LONG(0xF090675C)
	LONG(0xF090DA94)
	LONG(0xE8A0DAB8)
	LONG(0xF090675C)
	LONG(0xF090DA8C)
	LONG(0xE8A0DAB0)
	LONG(0xF090675C)
	LONG(0xF090DA84)
	LONG(0xE8A0DAA8)
	LONG(0xF090675C)
	LONG(0x64F4A240)
	LONG(0xB22E2258)
	LONG(0x6B00F400)
	LONG(0xF51FDA60)
	LONG(0xDA604B00)
	LONG(0xB22B6810)
	LONG(0x6B00F400)
	LONG(0xF51FDA60)
	LONG(0xDA604B00)
	LONG(0xFE941C1A)
	LONG(0x65006500)
	LONG(0x40114800)
	LONG(0x7740FE97)
	LONG(0x0)
	LONG(0x181A6500)
	LONG(0x6500FD63)
	LONG(0xFE9B1C1A)
	LONG(0x65006500)
	LONG(0x40024800)
	LONG(0x7740FE9E)
	LONG(0x0)
	LONG(0xB31C6500)
	LONG(0xEB43E22B)
	LONG(0x48FF60EE)
	LONG(0xB21A28DA)
	LONG(0xB21ADA00)
	LONG(0xB31ADA00)
	LONG(0x6C029B40)
	LONG(0xEA8CEC8B)
	LONG(0x6BFFDB40)
	LONG(0xB2114B01)
	LONG(0x1C1ADA60)
	LONG(0x6500FEAA)
	LONG(0x40024800)
	LONG(0x7740FEAD)
	LONG(0x0)
	LONG(0xF4006500)
	LONG(0xB30B6C00)
	LONG(0x1C1ADB80)
	LONG(0x6500FEB1)
	LONG(0x40044800)
	LONG(0x7740FEB4)
	LONG(0x0)
	LONG(0xB30A6500)
	LONG(0xEB83E453)
	LONG(0x647460EE)
	LONG(0x6500E8A0)
	LONG(0xBF886034)
	LONG(0xBF88603C)
	LONG(0x2625A0)
	LONG(0xBF885250)
	LONG(0xBF885070)
	LONG(0xBF885080)
	LONG(0x989680)
	LONG(0x679CB514)
	LONG(0xDCBCF070)
	LONG(0x9E60B613)
	LONG(0xEB4D6A01)
	LONG(0x6E4ADE60)
	LONG(0xDBC0B311)
	LONG(0xB612B311)
	LONG(0x3562EBAC)
	LONG(0xEF1167E5)
	LONG(0xDEE035A2)
	LONG(0xB60FED11)
	LONG(0xF600DEA0)
	LONG(0xB50E3362)
	LONG(0xB30EDD60)
	LONG(0x6D84DB40)
	LONG(0xDBA0B30D)
	LONG(0x6DFFB30D)
	LONG(0xB30DDBA0)
	LONG(0xF090DB40)
	LONG(0xE8A0C440)
	LONG(0xA0001800)
	LONG(0xBF885080)
	LONG(0xBF8852B0)
	LONG(0x1FFFFFFF)
	LONG(0xBF885270)
	LONG(0xBF8852C0)
	LONG(0xBF8852D0)
	LONG(0xBF885250)
	LONG(0xBF885070)
	LONG(0xBF885200)
	LONG(0xBF885210)
	LONG(0x1010112)
	LONG(0x40000002)
	LONG(0xA6620403)
	LONG(0x2010180)
	LONG(0x65000103)
	LONG(0x430209)
	LONG(0x80000102)
	LONG(0x409FA)
	LONG(0x2020100)
	LONG(0x24050001)
	LONG(0x4011000)
	LONG(0x5060224)
	LONG(0x1000624)
	LONG(0x12405)
	LONG(0x81050701)
	LONG(0x10000803)
	LONG(0x10409)
	LONG(0xA02)
	LONG(0x82050700)
	LONG(0x4002)
	LONG(0x2030507)
	LONG(0x40)
  } > kseg0_splitflash_mem
#endif

  .configs ORIGIN(configsfrs) :
  {
	LONG(0x0FFFFFFF)
	LONG(0xFFF979D9)
	LONG(0xFF6A0D5B)
	LONG(0x7FFFFFEB)
  } > configsfrs

  /* Boot Sections */
  .reset _RESET_ADDR :
  {
    KEEP(*(.reset))
  } > kseg0_program_mem
}

/* From here out every linker script is the same, so just include it */
/*INCLUDE "chipKIT-application-COMMON.ld"*/
